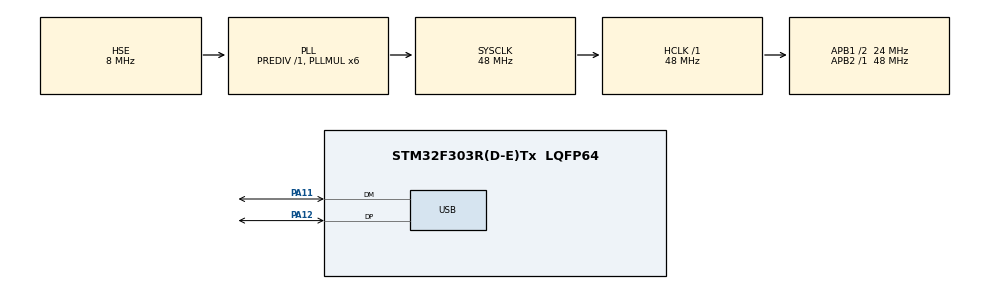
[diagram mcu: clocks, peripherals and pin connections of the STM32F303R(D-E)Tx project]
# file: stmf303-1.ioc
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Mcu.Family=STM32F3
Mcu.Name=STM32F303R(D-E)Tx
Mcu.Package=LQFP64
NVIC.PriorityGroup=NVIC_PRIORITYGROUP_4
NVIC.USB_HP_CAN_TX_IRQn=true\:0\:0\:false\:false\:true\:true\:true
NVIC.USB_LP_CAN_RX0_IRQn=true\:0\:0\:false\:false\:true\:false\:true
PA11.Mode=Device
PA11.Signal=USB_DM
PA12.Mode=Device
PA12.Signal=USB_DP
PA13.Mode=Serial_Wire
PA13.Signal=SYS_JTMS-SWDIO
PA14.Mode=Serial_Wire
PA14.Signal=SYS_JTCK-SWCLK
PF0-OSC_IN.Mode=HSE-External-Oscillator
PF0-OSC_IN.Signal=RCC_OSC_IN
PF1-OSC_OUT.Mode=HSE-External-Oscillator
PF1-OSC_OUT.Signal=RCC_OSC_OUT
ProjectManager.HeapSize=0x200
ProjectManager.StackSize=0x400
ProjectManager.TargetToolchain=STM32CubeIDE
RCC.AHBFreq_Value=48000000
RCC.APB1CLKDivider=RCC_HCLK_DIV2
RCC.APB1Freq_Value=24000000
RCC.APB1TimFreq_Value=48000000
RCC.APB2Freq_Value=48000000
RCC.APB2TimFreq_Value=48000000
RCC.CortexFreq_Value=48000000
RCC.HCLKFreq_Value=48000000
RCC.HSE_VALUE=8000000
RCC.HSI_VALUE=8000000
RCC.LSE_VALUE=32768
RCC.PLLMUL=RCC_PLL_MUL6
RCC.SYSCLKFreq_VALUE=48000000
RCC.SYSCLKSourceVirtual=RCC_SYSCLKSOURCE_PLLCLK
RCC.USBFreq_Value=48000000
USB_DEVICE.CLASS_NAME_FS=CDC
USB_DEVICE.VirtualMode=Cdc
USB_DEVICE.VirtualModeFS=Cdc_FS
VP_USB_DEVICE_VS_USB_DEVICE_CDC_FS.Mode=CDC_FS
board=custom

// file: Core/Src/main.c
/* USER CODE BEGIN Header */
/**
  ******************************************************************************
  * @file           : main.c
  * @brief          : Main program body
  ******************************************************************************
  * @attention
  *
  * <h2><center>&copy; Copyright (c) 2021 STMicroelectronics.
  * All rights reserved.</center></h2>
  *
  * This software component is licensed by ST under BSD 3-Clause license,
  * the "License"; You may not use this file except in compliance with the
  * License. You may obtain a copy of the License at:
  *                        opensource.org/licenses/BSD-3-Clause
  *
  ******************************************************************************
  */
/* USER CODE END Header */

#include "main.h"
#include "usb_device.h"

/* USER CODE BEGIN Includes */
#include "usbd_cdc_if.h"
#include "string.h"
/* USER CODE END Includes */

void SystemClock_Config(void);
static void MX_GPIO_Init(void);

/* USER CODE BEGIN 0 */
uint8_t *data = "AT+QIOPEN=1,0,\"TCP\",\"89.19.23.98\",9999,0,2";
uint8_t *data2 = "(char)26";
uint8_t my_buf[20] = "hello world \r\n";
/* USER CODE END 0 */

int main(void)
{

  /* MCU Configuration--------------------------------------------------------*/

  /* Reset of all peripherals, Initializes the Flash interface and the Systick. */
  HAL_Init();

  /* Configure the system clock */
  SystemClock_Config();

  /* Initialize all configured peripherals */
  MX_GPIO_Init();
  MX_USB_DEVICE_Init();

  /* Infinite loop */
  while (1)
  {

    /* USER CODE BEGIN 3 */
	  /*CDC_Transmit_FS (data, strlen (data));
	  	  CDC_Transmit_FS (data, strlen (data2));*/
	  CDC_Transmit_FS (my_buf, 14);
	  	  	  HAL_Delay(1000);
  }
  /* USER CODE END 3 */
}

void SystemClock_Config(void)
{
  RCC_OscInitTypeDef RCC_OscInitStruct = {0};
  RCC_ClkInitTypeDef RCC_ClkInitStruct = {0};
  RCC_PeriphCLKInitTypeDef PeriphClkInit = {0};

  /** Initializes the CPU, AHB and APB busses clocks
  */
  RCC_OscInitStruct.OscillatorType = RCC_OSCILLATORTYPE_HSE;
  RCC_OscInitStruct.HSEState = RCC_HSE_ON;
  RCC_OscInitStruct.HSIState = RCC_HSI_ON;
  RCC_OscInitStruct.PLL.PLLState = RCC_PLL_ON;
  RCC_OscInitStruct.PLL.PLLSource = RCC_PLLSOURCE_HSE;
  RCC_OscInitStruct.PLL.PLLMUL = RCC_PLL_MUL6;
  RCC_OscInitStruct.PLL.PREDIV = RCC_PREDIV_DIV1;
  if (HAL_RCC_OscConfig(&RCC_OscInitStruct) != HAL_OK)
  {
    Error_Handler();
  }
  /** Initializes the CPU, AHB and APB busses clocks
  */
  RCC_ClkInitStruct.ClockType = RCC_CLOCKTYPE_HCLK|RCC_CLOCKTYPE_SYSCLK
                              |RCC_CLOCKTYPE_PCLK1|RCC_CLOCKTYPE_PCLK2;
  RCC_ClkInitStruct.SYSCLKSource = RCC_SYSCLKSOURCE_PLLCLK;
  RCC_ClkInitStruct.AHBCLKDivider = RCC_SYSCLK_DIV1;
  RCC_ClkInitStruct.APB1CLKDivider = RCC_HCLK_DIV2;
  RCC_ClkInitStruct.APB2CLKDivider = RCC_HCLK_DIV1;

  if (HAL_RCC_ClockConfig(&RCC_ClkInitStruct, FLASH_LATENCY_1) != HAL_OK)
  {
    Error_Handler();
  }
  PeriphClkInit.PeriphClockSelection = RCC_PERIPHCLK_USB;
  PeriphClkInit.USBClockSelection = RCC_USBCLKSOURCE_PLL;
  if (HAL_RCCEx_PeriphCLKConfig(&PeriphClkInit) != HAL_OK)
  {
    Error_Handler();
  }
}

static void MX_GPIO_Init(void)
{

  /* GPIO Ports Clock Enable */
  __HAL_RCC_GPIOF_CLK_ENABLE();
  __HAL_RCC_GPIOA_CLK_ENABLE();

}

void Error_Handler(void)
{
}

/************************ (C) COPYRIGHT STMicroelectronics *****END OF FILE****/
